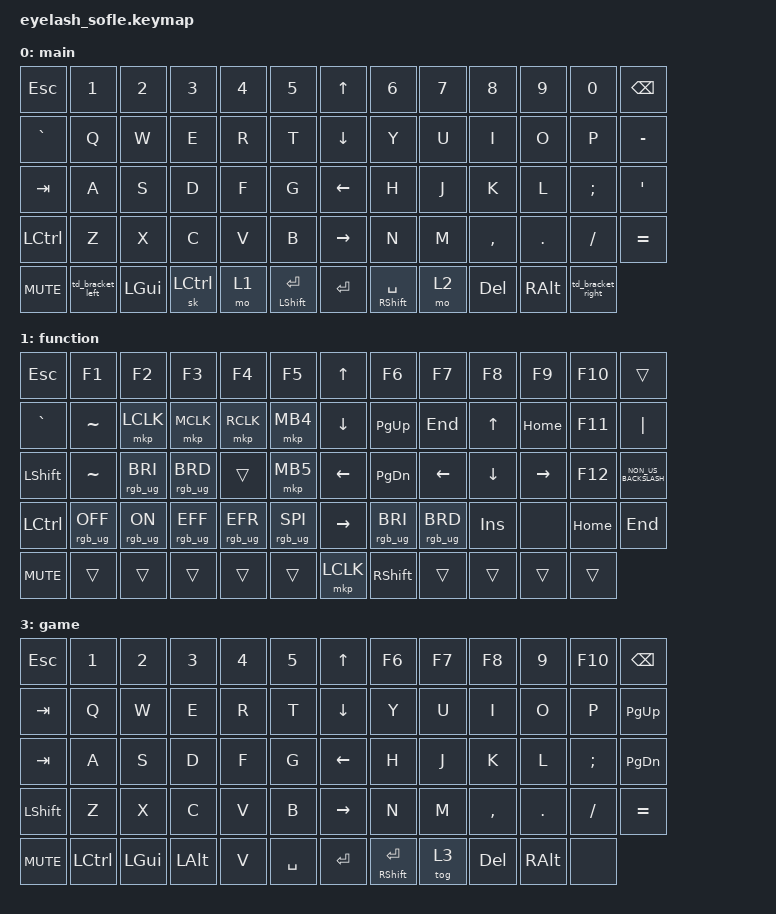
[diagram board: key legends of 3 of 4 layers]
#define ZMK_POINTING_DEFAULT_MOVE_VAL 1200  // 600
#define ZMK_POINTING_DEFAULT_SCRL_VAL 25   // 10

#include <input/processors.dtsi>
#include <zephyr/dt-bindings/input/input-event-codes.h>
#include <behaviors/anti_idle_mode.dtsi>
#include <dt-bindings/anti_idle_mode.h>
#include <behaviors.dtsi>
#include <dt-bindings/zmk/bt.h>
#include <dt-bindings/zmk/keys.h>
#include <dt-bindings/zmk/outputs.h>
#include <dt-bindings/zmk/pointing.h>
#include <dt-bindings/zmk/rgb.h>

&mmv_input_listener { input-processors = <&zip_xy_scaler 2 1>; };

&msc_input_listener { input-processors = <&zip_scroll_scaler 2 1>; };

&msc {
    acceleration-exponent = <1>;      // 0
    time-to-max-speed-ms = <100>;       // 300
    delay-ms = <0>;                   // 0
};

&mmv {
    time-to-max-speed-ms = <500>;
    acceleration-exponent = <1>;
    trigger-period-ms = <16>;
};

/ {
    anti_idle: anti_idle {
        compatible = "zmk,anti-idle-generic";
        #binding-cells = <0>;
        interval-ms = <60000>; // How often to send actions (ms)
        bindings = <&mmv MOVE_DOWN &mmv MOVE_UP>; // Actions to perform (e.g., mouse move)
        tap_ms = <40>;   // Duration of each action (ms)
        wait_ms = <200>; // Delay between actions (ms)
    };

    scroll_encoder: scroll_encoder {
        compatible = "zmk,behavior-sensor-rotate";
        #sensor-binding-cells = <0>;
        bindings = <&msc SCRL_DOWN>, <&msc SCRL_UP>;

        tap-ms = <100>;
    };

    td_bracket_left: td_bracket_left {
        compatible = "zmk,behavior-tap-dance";
        label = "TD_BRACKET_LEFT";
        #binding-cells = <0>;
        bindings = <&kp LEFT_BRACKET>, <&kp LS(LEFT_BRACKET)>;
    };

    td_bracket_right: td_bracket_right {
        compatible = "zmk,behavior-tap-dance";
        label = "TD_BRACKET_RIGHT";
        #binding-cells = <0>;
        bindings = <&kp RIGHT_BRACKET>, <&kp RIGHT_BRACE>;
    };

    tap_hold: tap_hold {
        compatible = "zmk,behavior-hold-tap";
        label = "TAP_HOLD";
        bindings = <&kp>, <&kp>;

        #binding-cells = <2>;
        tapping-term-ms = <150>;
        flavor = "tap-preferred";
    };

    behaviors {
    };

    keymap {
        compatible = "zmk,keymap";

        main {
            bindings = <
&kp ESC           &kp N1            &kp N2        &kp N3            &kp N4  &kp N5                        &kp UP_ARROW     &kp N6                       &kp N7  &kp N8      &kp N9         &kp N0             &kp BACKSPACE
&kp GRAVE         &kp Q             &kp W         &kp E             &kp R   &kp T                         &kp DOWN_ARROW   &kp Y                        &kp U   &kp I       &kp O          &kp P              &kp MINUS
&kp TAB           &kp A             &kp S         &kp D             &kp F   &kp G                         &kp LEFT_ARROW   &kp H                        &kp J   &kp K       &kp L          &kp SEMICOLON      &kp SQT
&kp LEFT_CONTROL  &kp Z             &kp X         &kp C             &kp V   &kp B                         &kp RIGHT_ARROW  &kp N                        &kp M   &kp COMMA   &kp DOT        &kp FSLH           &kp EQUAL
&kp C_MUTE        &td_bracket_left  &kp LEFT_GUI  &sk LEFT_CONTROL  &mo 1   &tap_hold LEFT_SHIFT ENTER    &kp ENTER        &tap_hold RIGHT_SHIFT SPACE  &mo 2   &kp DELETE  &kp RIGHT_ALT  &td_bracket_right
            >;

            sensor-bindings = <&inc_dec_kp C_VOLUME_UP C_VOL_DN>;
            display-name = "main";
            label = "main";
        };

        function {
            bindings = <
&kp ESCAPE        &kp F1           &kp F2           &kp F3           &kp F4           &kp F5             &kp UP_ARROW  &kp F6           &kp F7           &kp F8      &kp F9     &kp F10   &trans
&kp GRAVE         &kp TILDE        &mkp LCLK        &mkp MCLK        &mkp RCLK        &mkp MB4           &kp DOWN      &kp PG_UP        &kp END          &kp UP      &kp HOME   &kp F11   &kp PIPE
&kp LEFT_SHIFT    &kp TILDE        &rgb_ug RGB_BRI  &rgb_ug RGB_BRD  &trans           &mkp MB5           &kp LEFT      &kp PG_DN        &kp LEFT         &kp DOWN    &kp RIGHT  &kp F12   &kp NON_US_BACKSLASH
&kp LEFT_CONTROL  &rgb_ug RGB_OFF  &rgb_ug RGB_ON   &rgb_ug RGB_EFF  &rgb_ug RGB_EFR  &rgb_ug RGB_SPI    &kp RIGHT     &rgb_ug RGB_BRI  &rgb_ug RGB_BRD  &kp INSERT  &none      &kp HOME  &kp END
&kp C_MUTE        &trans           &trans           &trans           &trans           &trans             &mkp LCLK     &kp RIGHT_SHIFT  &trans           &trans      &trans     &trans
            >;

            display-name = "function";
            sensor-bindings = <&scroll_encoder>;
            label = "function";
        };

        bt {
            bindings = <
&kp TILDE  &bt BT_SEL 0  &bt BT_SEL 1    &bt BT_SEL 2  &bt BT_SEL 3       &bt BT_SEL 4          &mmv MOVE_UP     &kp F6  &kp F7  &kp F8      &kp F9     &kp F10      &bootloader
&trans     &bt BT_CLR    &bt BT_CLR_ALL  &trans        &none              &tog 3                &mmv MOVE_DOWN   &trans  &trans  &kp F11     &kp F12    &kp UNDER    &kp PLUS
&trans     &out OUT_USB  &out OUT_BLE    &trans        &trans             &trans                &mmv MOVE_LEFT   &trans  &trans  &trans      &trans     &kp LBRC     &kp RBRC
&trans     &sys_reset    &kp LG(X)       &kp LG(C)     &kp LG(V)          &trans                &mmv MOVE_RIGHT  &trans  &trans  &sys_reset  &soft_off  &bootloader  &trans
&trans     &trans        &trans          &trans        &anti_idle AIM_ON  &anti_idle AIM_OFF    &mkp LCLK        &trans  &trans  &trans      &trans     &trans
            >;

            display-name = "bt";
            sensor-bindings = <&scroll_encoder>;
            label = "bt";
        };

        game {
            display-name = "game";
            bindings = <
&kp ESC         &kp N1            &kp N2        &kp N3        &kp N4  &kp N5       &kp UP_ARROW     &kp F6                 &kp F7  &kp F8      &kp N9         &kp F10        &kp BACKSPACE
&kp TAB         &kp Q             &kp W         &kp E         &kp R   &kp T        &kp DOWN_ARROW   &kp Y                  &kp U   &kp I       &kp O          &kp P          &kp PAGE_UP
&kp TAB         &kp A             &kp S         &kp D         &kp F   &kp G        &kp LEFT_ARROW   &kp H                  &kp J   &kp K       &kp L          &kp SEMICOLON  &kp PAGE_DOWN
&kp LEFT_SHIFT  &kp Z             &kp X         &kp C         &kp V   &kp B        &kp RIGHT_ARROW  &kp N                  &kp M   &kp COMMA   &kp DOT        &kp FSLH       &kp EQUAL
&kp C_MUTE      &kp LEFT_CONTROL  &kp LEFT_GUI  &kp LEFT_ALT  &kp V   &kp SPACE    &kp ENTER        &mt RIGHT_SHIFT ENTER  &tog 3  &kp DELETE  &kp RIGHT_ALT  &none
            >;

            sensor-bindings = <&inc_dec_kp C_VOLUME_UP C_VOL_DN>;
            label = "game";
        };
    };
};
